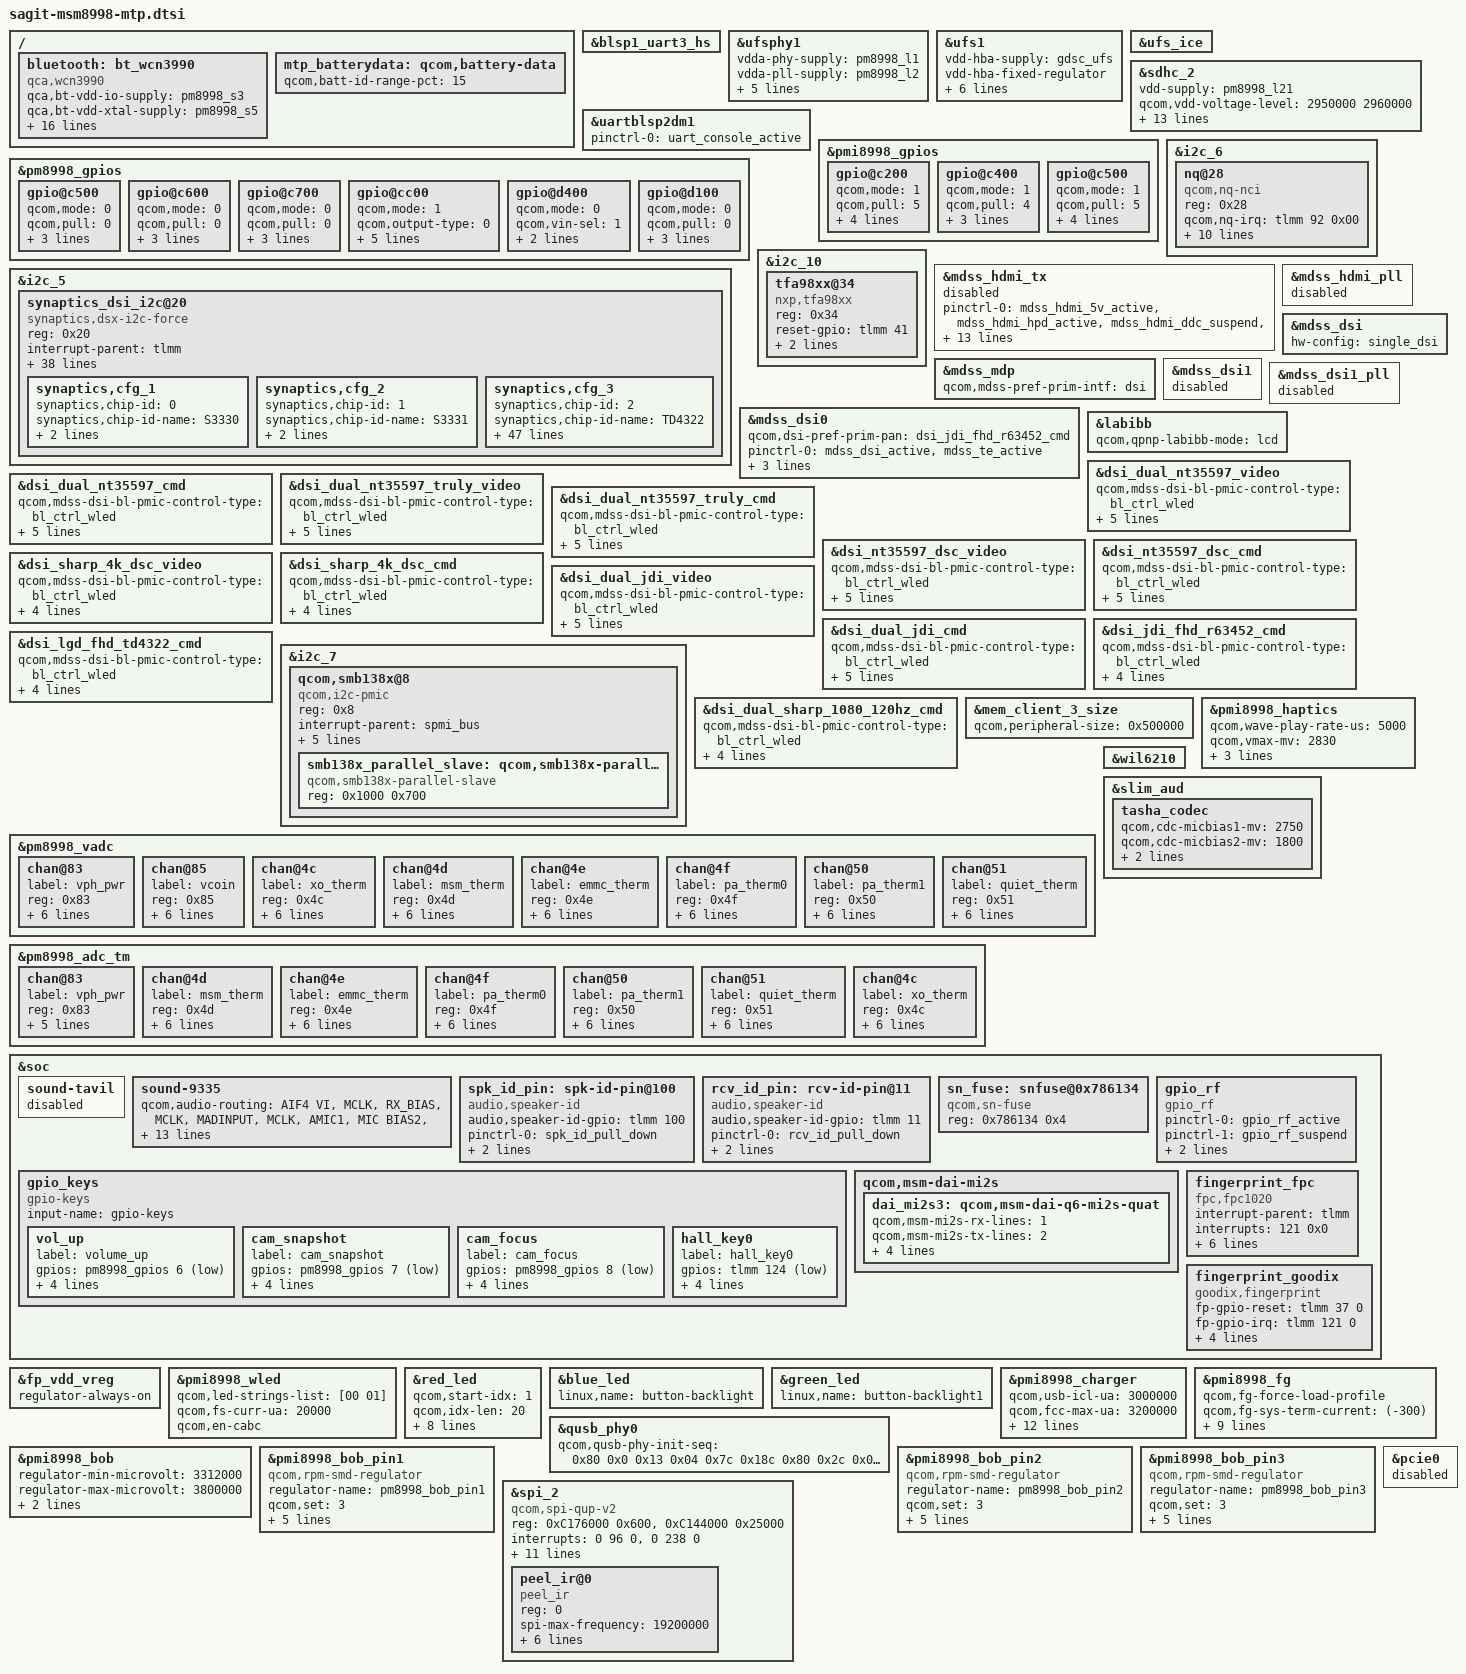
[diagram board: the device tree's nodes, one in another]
/* Copyright (c) 2016, The Linux Foundation. All rights reserved.
 * Copyright (C) 2018 XiaoMi, Inc.
 *
 * This program is free software; you can redistribute it and/or modify
 * it under the terms of the GNU General Public License version 2 and
 * only version 2 as published by the Free Software Foundation.
 *
 * This program is distributed in the hope that it will be useful,
 * but WITHOUT ANY WARRANTY; without even the implied warranty of
 * MERCHANTABILITY or FITNESS FOR A PARTICULAR PURPOSE.  See the
 * GNU General Public License for more details.
 */

#include <dt-bindings/interrupt-controller/irq.h>
#include "msm8998-pinctrl.dtsi"
#include "sagit-camera-sensor-mtp.dtsi"

/ {
	bluetooth: bt_wcn3990 {
		compatible = "qca,wcn3990";
		qca,bt-vdd-io-supply = <&pm8998_s3>;
		qca,bt-vdd-xtal-supply = <&pm8998_s5>;
		qca,bt-vdd-core-supply = <&pm8998_l7>;
		qca,bt-vdd-pa-supply = <&pm8998_l17>;
		qca,bt-vdd-ldo-supply = <&pm8998_l25>;
		qca,bt-chip-pwd-supply = <&pmi8998_bob_pin1>;
		clocks = <&clock_gcc clk_rf_clk2_pin>;
		clock-names = "rf_clk2";

		qca,bt-vdd-io-voltage-level = <1352000 1352000>;
		qca,bt-vdd-xtal-voltage-level = <2040000 2040000>;
		qca,bt-vdd-core-voltage-level = <1800000 1800000>;
		qca,bt-vdd-pa-voltage-level = <1304000 1304000>;
		qca,bt-vdd-ldo-voltage-level = <3312000 3312000>;
		qca,bt-chip-pwd-voltage-level = <3600000 3600000>;

		qca,bt-vdd-io-current-level = <1>; /* LPM/PFM */
		qca,bt-vdd-xtal-current-level = <1>; /* LPM/PFM */
		qca,bt-vdd-core-current-level = <1>; /* LPM/PFM */
		qca,bt-vdd-pa-current-level = <1>; /* LPM/PFM */
		qca,bt-vdd-ldo-current-level = <1>; /* LPM/PFM */
	};
};

&blsp1_uart3_hs {
	status = "ok";
};

&ufsphy1 {
	vdda-phy-supply = <&pm8998_l1>;
	vdda-pll-supply = <&pm8998_l2>;
	vddp-ref-clk-supply = <&pm8998_l26>;
	vdda-phy-max-microamp = <51400>;
	vdda-pll-max-microamp = <14600>;
	vddp-ref-clk-max-microamp = <100>;
	vddp-ref-clk-always-on;
	status = "ok";
};

&ufs1 {
	vdd-hba-supply = <&gdsc_ufs>;
	vdd-hba-fixed-regulator;
	vcc-supply = <&pm8998_l20>;
	vccq-supply = <&pm8998_l26>;
	vccq2-supply = <&pm8998_s4>;
	vcc-max-microamp = <750000>;
	vccq-max-microamp = <560000>;
	vccq2-max-microamp = <750000>;
	status = "ok";
};

&ufs_ice {
	status = "ok";
};

&sdhc_2 {
	vdd-supply = <&pm8998_l21>;
	qcom,vdd-voltage-level = <2950000 2960000>;
	qcom,vdd-current-level = <200 800000>;

	vdd-io-supply = <&pm8998_l13>;
	qcom,vdd-io-voltage-level = <1808000 2960000>;
	qcom,vdd-io-current-level = <200 22000>;

	pinctrl-names = "active", "sleep";
	pinctrl-0 = <&sdc2_clk_on  &sdc2_cmd_on &sdc2_data_on &sdc2_cd_on>;
	pinctrl-1 = <&sdc2_clk_off &sdc2_cmd_off &sdc2_data_off &sdc2_cd_off>;

	qcom,clk-rates = <400000 20000000 25000000
				50000000 100000000 200000000>;
	qcom,bus-speed-mode = "SDR12", "SDR25", "SDR50", "DDR50", "SDR104";

	cd-gpios = <&tlmm 95 0x1>;

	status = "ok";
};

&uartblsp2dm1 {
	status = "ok";
	pinctrl-names = "default";
	pinctrl-0 = <&uart_console_active>;
};

&pm8998_gpios {
	/* GPIO 6 for Vol+ Key */
	gpio@c500 {
		status = "okay";
		qcom,mode = <0>;
		qcom,pull = <0>;
		qcom,vin-sel = <0>;
		qcom,src-sel = <0>;
		qcom,out-strength = <1>;
	};

	/* GPIO 7 for Snapshot Key */
	gpio@c600 {
		status = "okay";
		qcom,mode = <0>;
		qcom,pull = <0>;
		qcom,vin-sel = <0>;
		qcom,src-sel = <0>;
		qcom,out-strength = <1>;
	};

	/* GPIO 8 for Focus Key */
	gpio@c700 {
		status = "okay";
		qcom,mode = <0>;
		qcom,pull = <0>;
		qcom,vin-sel = <0>;
		qcom,src-sel = <0>;
		qcom,out-strength = <1>;
	};

	gpio@cc00 { /* GPIO 13 */
		qcom,mode = <1>;
		qcom,output-type = <0>;
		qcom,pull = <5>;
		qcom,vin-sel = <0>;
		qcom,out-strength = <1>;
		qcom,src-sel = <3>;
		qcom,master-en = <1>;
		status = "okay";
	};

	/* GPIO 21 (NFC_CLK_REQ) */
	gpio@d400 {
		qcom,mode = <0>;
		qcom,vin-sel = <1>;
		qcom,src-sel = <0>;
		qcom,master-en = <1>;
		status = "okay";
	};

	/* GPIO 18 SMB138X */
	gpio@d100 {
		qcom,mode = <0>;
		qcom,pull = <0>;
		qcom,vin-sel = <0>;
		qcom,src-sel = <0>;
		qcom,master-en = <1>;
		status = "okay";
	};
};

&pmi8998_gpios {
	/* GPIO 3 for NS5S1153 AUDIO_SEL pin */
	gpio@c200 {
		status = "okay";
		qcom,mode = <1>;	/* Digital out */
		qcom,pull = <5>;	/* No pull */
		qcom,vin-sel = <1>;	/* 1.8v */
		qcom,src-sel = <0>;
		qcom,out-strength = <1>;
		qcom,master-en = <1>;
	};

	/* GPIO 5 for INFARED_DRV */
	gpio@c400 {
		status = "okay";
		qcom,mode = <1>;         /* QPNP_PIN_MODE_DIG_OUT */
		qcom,pull = <4>;                        /*PULL DOWN 10uA*/
		qcom,src-sel = <2>;             /*SPECIAL FUNCTION 1*/
		qcom,master-en = <1>;           /*ENABLE GPIO*/
		qcom,out-strength = <2>;        /*Medium strength current*/
	};

	/* GPIO 6 for the internal QNOVO discharge FET control signal */
	gpio@c500 {
		status = "okay";
		qcom,mode = <1>;
		qcom,pull = <5>;
		qcom,vin-sel = <0>;
		qcom,src-sel = <2>;
		qcom,out-strength = <1>;
		qcom,master-en = <1>;
	};
};

&i2c_5 {
	status = "okay";
	synaptics_dsi_i2c@20 {
		compatible = "synaptics,dsx-i2c-force";
		reg = <0x20>;
		interrupt-parent = <&tlmm>;
		interrupts = <125 0x2008>;
		vdd-supply = <&pm8998_l6>;
		lab-supply = <&lab_regulator>;
		ibb-supply = <&ibb_regulator>;
		disp-supply = <&pm8998_l14>;
		avdd-supply = <&disp_vddts_vreg>;
		synaptics,pwr-reg-name = "vdd";
		synaptics,lab-reg-name = "lab";
		synaptics,ibb-reg-name = "ibb";
		synaptics,disp-reg-name = "disp";
		synaptics,bus-reg-name = "avdd";
		synaptics,ub-i2c-addr = <0x2c>;
		pinctrl-names = "pmx_ts_active", "pmx_ts_suspend";
		pinctrl-0 = <&ts_active>;
		pinctrl-1 = <&ts_int_suspend &ts_reset_suspend>;
		synaptics,mdss-dsi-reset = <&tlmm 8 0>;
		synaptics,reset-gpio = <&tlmm 89 0x00>;
		synaptics,irq-gpio = <&tlmm 125 0x2008>;
		synaptics,reset-gpio-name = "dsx_reset";
		synaptics,irq-gpio-name = "dsx_irq";
		synaptics,irq-on-state = <0>;
		synaptics,irq-flags = <0x2008>; /* IRQF_ONESHOT | IRQF_TRIGGER_LOW */
		synaptics,power-delay-ms = <5>;
		synaptics,reset-delay-ms = <200>;
		synaptics,reset-active-ms = <5>;
		synaptics,power-on-state = <1>;
		synaptics,reset-on-state = <0>;
		synaptics,mdss-reset-state = <1>;
		synaptics,panel-is-incell;
		synaptics,cap-button-codes = <158 139 102>;
		synaptics,short-jdi-25 = "000: 0xfb\n001: 0xef\n002: 0xff\n003: 0xff\n004: 0x18\n005: 0x00\n006: 0x00";
		synaptics,short-jdi-26 = "000: 0x03\n001: 0x00\n002: 0x00\n003: 0x00\n004: 0x00\n005: 0x00\n006: 0x00";
		clock-names = "iface_clk", "core_clk";
		clocks = <&clock_gcc clk_gcc_blsp1_ahb_clk>,
			 <&clock_gcc clk_gcc_blsp1_qup5_i2c_apps_clk>;
		synaptics,guest-serialization-as-lockdown;
		synaptics,tp-id-byte = /bits/ 8 <0>;
		synaptics,config-array-size = <3>;
		synaptics,cfg_1 {
			synaptics,chip-id = <0>;
			synaptics,chip-id-name = "S3330";
			synaptics,tp-id = /bits/ 8 <0x31>;
			synaptics,fw-name = "synaptics_jdi_3330_c1.fw";
		};
		synaptics,cfg_2 {
			synaptics,chip-id = <1>;
			synaptics,chip-id-name = "S3331";
			synaptics,tp-id = /bits/ 8 <0x31>;
			synaptics,fw-name = "synaptics_jdi_3331_c1.fw";
		};
		synaptics,cfg_3 {
			synaptics,chip-id = <2>;
			synaptics,chip-id-name = "TD4322";
			synaptics,chip-is-tddi;

			synaptics,factory-param;
			synaptics,tddi-short-limit_b = <150>;
			synaptics,tddi-noise-limit	= <60>;
			synaptics,tddi-extend-ee-short-reset-dur = <60>;
			synaptics,tddi-extend-ee-short-int_dur = <150>;
			synaptics,tddi-extend-ee-short-tx-on-count = <146>;
			synaptics,tddi-extend-ee-short-rx-on-count = <146>;
			synaptics,tddi-extend-ee-short-test-limit-part1 = <180>;
			synaptics,tddi-extend-ee-short-test-limit-part2 = <0>;

			synaptics,tddi-open-test-int-dur-one = <145>;
			synaptics,tddi-open-test-int-dur-two = <15>;
			synaptics,tddi-open-test-limit-phase2-lower = <50>;

			synaptics,tddi-b7-open-test-int-dur-one = <23>;
			synaptics,tddi-b7-open-test-int-dur-two = <27>;
			synaptics,tddi-b7-open-test-limit-phase2-lower = <0>;
			synaptics,tddi-b7-open-test-limit-phase2-upper = <115>;
			synaptics,button-count = <2>;
			synaptics,abs-0d-open-factor = <9>;
			synaptics,abs-0d-open-test-limit = <30>;

			synaptics,elec-open-test-tx-on-count = <2>;
			synaptics,elec-open-test-rx-on-count = <2>;
			synaptics,elec-open-int-dur-one = <10>;
			synaptics,elec-open-int-dur-two = <15>;
			synaptics,elec-open-test-limit-one = <0>;
			synaptics,elec-open-test-limit-two = <50>;

			synaptics,disp-pre-on-sleep = <10>;
			synaptics,disp-post-on-sleep = <10>;
			synaptics,disp-pre-off-sleep = <10>;
			synaptics,disp-post-off-sleep = <0>;
			synaptics,lab-pre-on-sleep = <0>;
			synaptics,lab-post-on-sleep = <10>;
			synaptics,lab-pre-off-sleep = <10>;
			synaptics,lab-post-off-sleep = <0>;
			synaptics,ibb-pre-on-sleep = <0>;
			synaptics,ibb-post-on-sleep = <10>;
			synaptics,ibb-pre-off-sleep = <10>;
			synaptics,ibb-post-off-sleep = <0>;
			synaptics,tp-id = /bits/ 8 <0x34>;
			synaptics,fw-name = "synaptics_lgd_4322_c1.fw";
		};
	};
};

&i2c_6 { /* BLSP1 QUP6 (NFC) */
	status = "okay";
	nq@28 {
		compatible = "qcom,nq-nci";
		reg = <0x28>;
		qcom,nq-irq = <&tlmm 92 0x00>;
		qcom,nq-ven = <&tlmm 12 0x00>;
		qcom,nq-firm = <&tlmm 93 0x00>;
		qcom,nq-clkreq = <&pm8998_gpios 21 0x00>;
		qcom,nq-esepwr = <&tlmm 116 0x00>;
		interrupt-parent = <&tlmm>;
		qcom,clk-src = "BBCLK3";
		interrupts = <92 0>;
		interrupt-names = "nfc_irq";
		pinctrl-names = "nfc_active", "nfc_suspend";
		pinctrl-0 = <&nfc_int_active &nfc_enable_active>;
		pinctrl-1 = <&nfc_int_suspend &nfc_enable_suspend>;
		clocks = <&clock_gcc clk_ln_bb_clk3_pin>;
		clock-names = "ref_clk";
	};
};

&i2c_10 { /* BLSP2 QUP4 (Audio Smart Pa)*/
	status = "okay";
	tfa98xx@34 {
		compatible = "nxp,tfa98xx";
		reg = <0x34>;
		reset-gpio = <&tlmm 41 0>;
		irq-gpio = <&tlmm 42 0>;
		spk-id = <&spk_id_pin>;
	};
};

&mdss_hdmi_tx {
	status = "disabled";
	pinctrl-names = "hdmi_hpd_active", "hdmi_ddc_active", "hdmi_cec_active",
				"hdmi_active", "hdmi_sleep";
	pinctrl-0 = <&mdss_hdmi_5v_active  &mdss_hdmi_hpd_active
			&mdss_hdmi_ddc_suspend &mdss_hdmi_cec_suspend>;
	pinctrl-1 = <&mdss_hdmi_5v_active &mdss_hdmi_hpd_active
			&mdss_hdmi_ddc_active &mdss_hdmi_cec_suspend>;
	pinctrl-2 = <&mdss_hdmi_5v_active &mdss_hdmi_hpd_active
			&mdss_hdmi_cec_active &mdss_hdmi_ddc_suspend>;
	pinctrl-3 = <&mdss_hdmi_5v_active &mdss_hdmi_hpd_active
			&mdss_hdmi_ddc_active &mdss_hdmi_cec_active>;
	pinctrl-4 = <&mdss_hdmi_5v_suspend &mdss_hdmi_hpd_suspend
			&mdss_hdmi_ddc_suspend &mdss_hdmi_cec_suspend>;
};

&mdss_hdmi_pll {
	status = "disabled";
};

&mdss_mdp {
	qcom,mdss-pref-prim-intf = "dsi";
};

&mdss_dsi {
	hw-config = "single_dsi";
};

&mdss_dsi0 {
	qcom,dsi-pref-prim-pan = <&dsi_jdi_fhd_r63452_cmd>;
	pinctrl-names = "mdss_default", "mdss_sleep";
	pinctrl-0 = <&mdss_dsi_active &mdss_te_active>;
	pinctrl-1 = <&mdss_dsi_suspend &mdss_te_suspend>;
	qcom,platform-reset-gpio = <&tlmm 94 0>;
	qcom,platform-te-gpio = <&tlmm 10 0>;
};

&mdss_dsi1 {
	status = "disabled";
};

&mdss_dsi1_pll {
	status = "disabled";
};

&labibb {
	status = "ok";
	qcom,qpnp-labibb-mode = "lcd";
};

&dsi_dual_nt35597_video {
	qcom,mdss-dsi-bl-pmic-control-type = "bl_ctrl_wled";
	qcom,mdss-dsi-bl-min-level = <1>;
	qcom,mdss-dsi-bl-max-level = <4095>;
	qcom,mdss-dsi-mode-sel-gpio-state = "dual_port";
	qcom,panel-supply-entries = <&dsi_panel_pwr_supply>;
};

&dsi_dual_nt35597_cmd {
	qcom,mdss-dsi-bl-pmic-control-type = "bl_ctrl_wled";
	qcom,mdss-dsi-bl-min-level = <1>;
	qcom,mdss-dsi-bl-max-level = <4095>;
	qcom,mdss-dsi-mode-sel-gpio-state = "dual_port";
	qcom,panel-supply-entries = <&dsi_panel_pwr_supply>;
};

&dsi_dual_nt35597_truly_video {
	qcom,mdss-dsi-bl-pmic-control-type = "bl_ctrl_wled";
	qcom,mdss-dsi-bl-min-level = <1>;
	qcom,mdss-dsi-bl-max-level = <4095>;
	qcom,mdss-dsi-mode-sel-gpio-state = "dual_port";
	qcom,panel-supply-entries = <&dsi_panel_pwr_supply>;
};

&dsi_dual_nt35597_truly_cmd {
	qcom,mdss-dsi-bl-pmic-control-type = "bl_ctrl_wled";
	qcom,mdss-dsi-bl-min-level = <1>;
	qcom,mdss-dsi-bl-max-level = <4095>;
	qcom,mdss-dsi-mode-sel-gpio-state = "dual_port";
	qcom,panel-supply-entries = <&dsi_panel_pwr_supply>;
};

&dsi_nt35597_dsc_video {
	qcom,mdss-dsi-bl-pmic-control-type = "bl_ctrl_wled";
	qcom,mdss-dsi-bl-min-level = <1>;
	qcom,mdss-dsi-bl-max-level = <4095>;
	qcom,mdss-dsi-mode-sel-gpio-state = "single_port";
	qcom,panel-supply-entries = <&dsi_panel_pwr_supply>;
};

&dsi_nt35597_dsc_cmd {
	qcom,mdss-dsi-bl-pmic-control-type = "bl_ctrl_wled";
	qcom,mdss-dsi-bl-min-level = <1>;
	qcom,mdss-dsi-bl-max-level = <4095>;
	qcom,mdss-dsi-mode-sel-gpio-state = "single_port";
	qcom,panel-supply-entries = <&dsi_panel_pwr_supply>;
};

&dsi_sharp_4k_dsc_video {
	qcom,mdss-dsi-bl-pmic-control-type = "bl_ctrl_wled";
	qcom,mdss-dsi-bl-min-level = <1>;
	qcom,mdss-dsi-bl-max-level = <4095>;
	qcom,panel-supply-entries = <&dsi_panel_pwr_supply>;
};

&dsi_sharp_4k_dsc_cmd {
	qcom,mdss-dsi-bl-pmic-control-type = "bl_ctrl_wled";
	qcom,mdss-dsi-bl-min-level = <1>;
	qcom,mdss-dsi-bl-max-level = <4095>;
	qcom,panel-supply-entries = <&dsi_panel_pwr_supply>;
};

&dsi_dual_jdi_video {
	qcom,mdss-dsi-bl-pmic-control-type = "bl_ctrl_wled";
	qcom,mdss-dsi-bl-min-level = <1>;
	qcom,mdss-dsi-bl-max-level = <4095>;
	qcom,5v-boost-gpio = <&tlmm 51 0>;
	qcom,panel-supply-entries = <&dsi_panel_pwr_supply>;
};

&dsi_dual_jdi_cmd {
	qcom,mdss-dsi-bl-pmic-control-type = "bl_ctrl_wled";
	qcom,mdss-dsi-bl-min-level = <1>;
	qcom,mdss-dsi-bl-max-level = <4095>;
	qcom,5v-boost-gpio = <&tlmm 51 0>;
	qcom,panel-supply-entries = <&dsi_panel_pwr_supply>;
};

&dsi_jdi_fhd_r63452_cmd {
	qcom,mdss-dsi-bl-pmic-control-type = "bl_ctrl_wled";
	qcom,mdss-dsi-bl-min-level = <1>;
	qcom,mdss-dsi-bl-max-level = <4095>;
	qcom,panel-supply-entries = <&dsi_panel_pwr_supply>;
};

&dsi_lgd_fhd_td4322_cmd {
	qcom,mdss-dsi-bl-pmic-control-type = "bl_ctrl_wled";
	qcom,mdss-dsi-bl-min-level = <1>;
	qcom,mdss-dsi-bl-max-level = <4095>;
	qcom,panel-supply-entries = <&dsi_panel_pwr_supply_lgd_td4322>;
};

&i2c_7 {
	status = "okay";
	qcom,smb138x@8 {
		compatible = "qcom,i2c-pmic";
		reg = <0x8>;
		#address-cells = <2>;
		#size-cells = <0>;
		interrupt-parent = <&spmi_bus>;
		interrupts = <0x0 0xd1 0x0 IRQ_TYPE_LEVEL_LOW>;
		interrupt_names = "smb138x";
		interrupt-controller;
		#interrupt-cells = <3>;
		qcom,periph-map = <0x10 0x11 0x12 0x13 0x14 0x16 0x36>;
		smb138x_parallel_slave: qcom,smb138x-parallel-slave@1000 {
			compatible = "qcom,smb138x-parallel-slave";
			reg = <0x1000 0x700>;
		};
	};
};

&dsi_dual_sharp_1080_120hz_cmd {
	qcom,mdss-dsi-bl-pmic-control-type = "bl_ctrl_wled";
	qcom,mdss-dsi-bl-min-level = <1>;
	qcom,mdss-dsi-bl-max-level = <4095>;
	qcom,panel-supply-entries = <&dsi_panel_pwr_supply>;
};

&mem_client_3_size {
	qcom,peripheral-size = <0x500000>;
};

&pmi8998_haptics {
	status = "okay";
	qcom,wave-play-rate-us = <5000>;
	qcom,vmax-mv = <2830>;
	qcom,wave-shape = "sine";
	qcom,brake-pattern = [03 02 00 00];
	qcom,misc-trim-error-rc19p2-clk-reg-present;
};

&pm8998_vadc {
	chan@83 {
		label = "vph_pwr";
		reg = <0x83>;
		qcom,decimation = <2>;
		qcom,pre-div-channel-scaling = <1>;
		qcom,calibration-type = "absolute";
		qcom,scale-function = <0>;
		qcom,hw-settle-time = <0>;
		qcom,fast-avg-setup = <0>;
	};

	chan@85 {
		label = "vcoin";
		reg = <0x85>;
		qcom,decimation = <2>;
		qcom,pre-div-channel-scaling = <1>;
		qcom,calibration-type = "absolute";
		qcom,scale-function = <0>;
		qcom,hw-settle-time = <0>;
		qcom,fast-avg-setup = <0>;
	};

	chan@4c {
		label = "xo_therm";
		reg = <0x4c>;
		qcom,decimation = <2>;
		qcom,pre-div-channel-scaling = <0>;
		qcom,calibration-type = "ratiometric";
		qcom,scale-function = <4>;
		qcom,hw-settle-time = <2>;
		qcom,fast-avg-setup = <0>;
	};

	chan@4d {
		label = "msm_therm";
		reg = <0x4d>;
		qcom,decimation = <2>;
		qcom,pre-div-channel-scaling = <0>;
		qcom,calibration-type = "ratiometric";
		qcom,scale-function = <2>;
		qcom,hw-settle-time = <2>;
		qcom,fast-avg-setup = <0>;
	};

	chan@4e {
		label = "emmc_therm";
		reg = <0x4e>;
		qcom,decimation = <2>;
		qcom,pre-div-channel-scaling = <0>;
		qcom,calibration-type = "ratiometric";
		qcom,scale-function = <2>;
		qcom,hw-settle-time = <2>;
		qcom,fast-avg-setup = <0>;
	};

	chan@4f {
		label = "pa_therm0";
		reg = <0x4f>;
		qcom,decimation = <2>;
		qcom,pre-div-channel-scaling = <0>;
		qcom,calibration-type = "ratiometric";
		qcom,scale-function = <2>;
		qcom,hw-settle-time = <2>;
		qcom,fast-avg-setup = <0>;
	};

	chan@50 {
		label = "pa_therm1";
		reg = <0x50>;
		qcom,decimation = <2>;
		qcom,pre-div-channel-scaling = <0>;
		qcom,calibration-type = "ratiometric";
		qcom,scale-function = <2>;
		qcom,hw-settle-time = <2>;
		qcom,fast-avg-setup = <0>;
	};

	chan@51 {
		label = "quiet_therm";
		reg = <0x51>;
		qcom,decimation = <2>;
		qcom,pre-div-channel-scaling = <0>;
		qcom,calibration-type = "ratiometric";
		qcom,scale-function = <2>;
		qcom,hw-settle-time = <2>;
		qcom,fast-avg-setup = <0>;
	};
};

&pm8998_adc_tm {
	chan@83 {
		label = "vph_pwr";
		reg = <0x83>;
		qcom,pre-div-channel-scaling = <1>;
		qcom,calibration-type = "absolute";
		qcom,scale-function = <0>;
		qcom,hw-settle-time = <0>;
		qcom,btm-channel-number = <0x60>;
	};

	chan@4d {
		label = "msm_therm";
		reg = <0x4d>;
		qcom,pre-div-channel-scaling = <0>;
		qcom,calibration-type = "ratiometric";
		qcom,scale-function = <2>;
		qcom,hw-settle-time = <2>;
		qcom,btm-channel-number = <0x68>;
		qcom,thermal-node;
	};

	chan@4e {
		label = "emmc_therm";
		reg = <0x4e>;
		qcom,pre-div-channel-scaling = <0>;
		qcom,calibration-type = "ratiometric";
		qcom,scale-function = <2>;
		qcom,hw-settle-time = <2>;
		qcom,btm-channel-number = <0x80>;
		qcom,thermal-node;
	};

	chan@4f {
		label = "pa_therm0";
		reg = <0x4f>;
		qcom,pre-div-channel-scaling = <0>;
		qcom,calibration-type = "ratiometric";
		qcom,scale-function = <2>;
		qcom,hw-settle-time = <2>;
		qcom,btm-channel-number = <0x88>;
		qcom,thermal-node;
	};

	chan@50 {
		label = "pa_therm1";
		reg = <0x50>;
		qcom,pre-div-channel-scaling = <0>;
		qcom,calibration-type = "ratiometric";
		qcom,scale-function = <2>;
		qcom,hw-settle-time = <2>;
		qcom,btm-channel-number = <0x90>;
		qcom,thermal-node;
	};

	chan@51 {
		label = "quiet_therm";
		reg = <0x51>;
		qcom,pre-div-channel-scaling = <0>;
		qcom,calibration-type = "ratiometric";
		qcom,scale-function = <2>;
		qcom,hw-settle-time = <2>;
		qcom,btm-channel-number = <0x70>;
		qcom,thermal-node;
	};

	chan@4c {
		label = "xo_therm";
		reg = <0x4c>;
		qcom,pre-div-channel-scaling = <0>;
		qcom,calibration-type = "ratiometric";
		qcom,scale-function = <4>;
		qcom,hw-settle-time = <2>;
		qcom,btm-channel-number = <0x78>;
		qcom,thermal-node;
	};
};

&wil6210 {
	status = "ok";
};

&slim_aud {
	tasha_codec {
		qcom,cdc-micbias1-mv = <2750>;
		qcom,cdc-micbias2-mv = <1800>;
		qcom,cdc-micbias3-mv = <1800>;
		qcom,cdc-micbias4-mv = <2750>;
	};
};

&soc {
	sound-tavil {
		status = "disabled";
	};

	sound-9335 {
		qcom,audio-routing =
			"AIF4 VI", "MCLK",
			"RX_BIAS", "MCLK",
			"MADINPUT", "MCLK",
			"AMIC1", "MIC BIAS2",
			"MIC BIAS2", "Handset Mic",
			"AMIC2", "MIC BIAS2",
			"MIC BIAS2", "Headset Mic",
			"AMIC3", "MIC BIAS1",
			"MIC BIAS1", "ANCRight Headset Mic",
			"AMIC4", "MIC BIAS1",
			"MIC BIAS1", "ANCLeft Headset Mic",
			"AMIC5", "MIC BIAS4",
			"MIC BIAS4", "Handset Mic",
			"AMIC6", "MIC BIAS4",
			"MIC BIAS4", "Analog Mic6";

		qcom,wsa-max-devs = <0>;
		qcom,msm-mbhc-hphl-swh = <1>;
		qcom,us-euro-gpios = <&wcd_us_euro_gpio>;

		qcom,asel-gpio = <&pmi8998_gpios 3 0x00>;
		qcom,hsdet-gpio = <&tlmm 8 0x01>;

		qcom,spk-id-pin = <&spk_id_pin>;
		qcom,rcv-id-pin = <&rcv_id_pin>;
	};

	spk_id_pin: spk-id-pin@100 {
		compatible = "audio,speaker-id";
		audio,speaker-id-gpio = <&tlmm 100 0x00>;
		pinctrl-names = "pull_down", "pull_up", "no_pull";
		pinctrl-0 = <&spk_id_pull_down>;
		pinctrl-1 = <&spk_id_pull_up>;
		pinctrl-2 = <&spk_id_no_pull>;
	};

	rcv_id_pin: rcv-id-pin@11 {
		compatible = "audio,speaker-id";
		audio,speaker-id-gpio = <&tlmm 11 0x00>;
		pinctrl-names = "pull_down", "pull_up", "no_pull";
		pinctrl-0 = <&rcv_id_pull_down>;
		pinctrl-1 = <&rcv_id_pull_up>;
		pinctrl-2 = <&rcv_id_no_pull>;
	};

	sn_fuse: snfuse@0x786134 {
		compatible = "qcom,sn-fuse";
		reg = <0x786134 0x4>;
		reg-names = "sn-base";
	};

	gpio_keys {
		compatible = "gpio-keys";
		input-name = "gpio-keys";
		status = "okay";

		vol_up {
			label = "volume_up";
			gpios = <&pm8998_gpios 6 0x1>;
			linux,input-type = <1>;
			linux,code = <115>;
			gpio-key,wakeup;
			debounce-interval = <15>;
		};

		cam_snapshot {
			label = "cam_snapshot";
			gpios = <&pm8998_gpios 7 0x1>;
			linux,input-type = <1>;
			linux,code = <766>;
			gpio-key,wakeup;
			debounce-interval = <15>;
		};

		cam_focus {
			label = "cam_focus";
			gpios = <&pm8998_gpios 8 0x1>;
			linux,input-type = <1>;
			linux,code = <528>;
			gpio-key,wakeup;
			debounce-interval = <15>;
		};

		hall_key0 {
			label = "hall_key0";
			gpios = <&tlmm 124 0x01>;
			linux,input-type = <5>;
			linux,code = <0>;
			gpio-key,wakeup;
			debounce-interval = <15>;
		};
	};

	gpio_rf {
		pinctrl-names = "tlmm_gpio_rf_active","tlmm_gpio_rf_suspend";
		pinctrl-0 = <&gpio_rf_active>;
		pinctrl-1 = <&gpio_rf_suspend>;
		compatible = "gpio_rf";
		gpios = <&tlmm 119 0x01>;
		debounce-interval = <15>;
	};

	qcom,msm-dai-mi2s {
		dai_mi2s3: qcom,msm-dai-q6-mi2s-quat {
			qcom,msm-mi2s-rx-lines = <1>;
			qcom,msm-mi2s-tx-lines = <2>;
			pinctrl-names = "default", "sleep";
			pinctrl-0 = <&quat_mi2s_active
				     &quat_mi2s_sd0_active
				     &quat_mi2s_sd1_active>;
			pinctrl-1 = <&quat_mi2s_sleep
				     &quat_mi2s_sd0_sleep
				     &quat_mi2s_sd1_sleep>;
		};
	};

	fingerprint_fpc {
		status = "ok";
		compatible = "fpc,fpc1020";
		interrupt-parent = <&tlmm>;
		interrupts = <121 0x0>;
		fpc,gpio_rst    = <&tlmm 37 0x0>;
		fpc,gpio_irq    = <&tlmm 121 0x0>;
		vdd_ana-supply  = <&fp_vdd_vreg>;
		/* fpc,enable-on-boot; */
		/* fpc,enable-wakeup; */

		pinctrl-names = "fpc1020_reset_reset",
			"fpc1020_reset_active",
			"fpc1020_irq_active";

		pinctrl-0 = <&msm_gpio_37>;
		pinctrl-1 = <&msm_gpio_37_output_high>;
		pinctrl-2 = <&msm_gpio_121>;
	};

	fingerprint_goodix {
		compatible = "goodix,fingerprint";
		fp-gpio-reset = <&tlmm 37 0>;
		fp-gpio-irq = <&tlmm 121 0>;
		pinctrl-names = "pmx_fp_active", "pmx_fp_suspend";
		pinctrl-0 = <&fp_active>;
		pinctrl-1 = <&fp_suspend>;
		clock-names = "iface_clk", "core_clk";
		clocks = <&clock_gcc clk_gcc_blsp2_ahb_clk>,
			<&clock_gcc clk_gcc_blsp2_qup6_spi_apps_clk>;
		status = "ok";
	};
};

&fp_vdd_vreg {
	regulator-always-on;
};

&pmi8998_wled {
	qcom,led-strings-list = [00 01];
	qcom,fs-curr-ua = <20000>;
	qcom,en-cabc;
};

/* Red led was used for powersupply of White led */
&red_led {
	qcom,start-idx = <1>;
	qcom,idx-len = <20>;
	qcom,duty-pcts = [00 06 10 20 32 44 54 5e 64 64
			64 5e 54 44 32 20 10 06 00 00];
	qcom,lut-flags = <3>;
	qcom,pause-lo = <0>;
	qcom,pause-hi = <0>;
	qcom,ramp-step-ms = <128>;
	qcom,use-blink;
	linux,name = "white";
};

/* Blue led was used for powersupply of left button key backlight */
&blue_led {
		 linux,name = "button-backlight";
};

/* Green led was used for powersupply of right button key backlight */
&green_led {
		 linux,name = "button-backlight1";
};
&pmi8998_charger {
		 qcom,usb-icl-ua = <3000000>;
		 qcom,fcc-max-ua = <3200000>;
		 qcom,fcc-low-temp-delta = <2875000>;
		 qcom,fcc-hot-temp-delta = <1600000>;
		 qcom,fcc-cool-temp-delta = <2225000>;
		 qcom,auto-recharge-soc;

		 qcom,thermal-mitigation
								= <1800000 1600000 1400000 1200000 1000000 1000000 1000000>;
		 qcom,thermal-mitigation-dcp
								= <1800000 1600000 1400000 1200000 1000000 1000000 1000000>;
		 qcom,thermal-mitigation-qc3
								= <3000000 2425000 2125000 1825000 1525000 1225000 750000>;
		 qcom,thermal-mitigation-qc2
								= <1600000 1400000 1200000 1000000 900000 900000 550000>;
};
&pmi8998_fg {
		 qcom,fg-force-load-profile;
		 qcom,fg-sys-term-current = <(-300)>;
		 qcom,fg-chg-term-current = <200>;
		 qcom,fg-auto-recharge-soc;
		 qcom,fg-recharge-soc-thr = <99>;
		 qcom,fg-cutoff-voltage = <3400>;
		 qcom,fg-empty-voltage = <3100>;
		 qcom,fg-jeita-hyst-temp = <0>;
		 qcom,fg-jeita-thresholds = <0 15 45 58>;
		 qcom,fg-esr-clamp-mohms = <60>;
		 qcom,fg-batt-temp-delta = <6>;
};
/{
	mtp_batterydata: qcom,battery-data {
		qcom,batt-id-range-pct = <15>;
		#include "batterydata-c1-atl-3350mAh.dtsi"
		#include "batterydata-c1-sdi-3440mAh.dtsi"
		#include "batterydata-itech-3020mAh.dtsi"
	};
};

&qusb_phy0 {
	qcom,qusb-phy-init-seq =
				/* <value reg_offset> */
				<0x80 0x0
				0x13 0x04
				0x7c 0x18c
				0x80 0x2c
				0x0a 0x184
				0xf0 0x23c
				0x0d 0x240>;
};

&pmi8998_bob {
		 regulator-min-microvolt = <3312000>;
		 regulator-max-microvolt = <3800000>;
		 qcom,bob-pwm-threshold-current = <2000000>;
		 qcom,init-bob-mode = <2>;
		 status = "okay";
};
&pmi8998_bob_pin1 {
		 compatible = "qcom,rpm-smd-regulator";
		 regulator-name = "pm8998_bob_pin1";
		 qcom,set = <3>;
		 regulator-min-microvolt = <3312000>;
		 regulator-max-microvolt = <3800000>;
		 qcom,bob-pwm-threshold-current = <2000000>;
		 qcom,init-bob-mode = <2>;
		 qcom,use-pin-ctrl-voltage1;
};
&pmi8998_bob_pin2 {
		 compatible = "qcom,rpm-smd-regulator";
		 regulator-name = "pm8998_bob_pin2";
		 qcom,set = <3>;
		 regulator-min-microvolt = <3312000>;
		 regulator-max-microvolt = <3800000>;
		 qcom,bob-pwm-threshold-current = <2000000>;
		 qcom,init-bob-mode = <2>;
		 qcom,use-pin-ctrl-voltage2;
};
&pmi8998_bob_pin3 {
		 compatible = "qcom,rpm-smd-regulator";
		 regulator-name = "pm8998_bob_pin3";
		 qcom,set = <3>;
		 regulator-min-microvolt = <3312000>;
		 regulator-max-microvolt = <3800000>;
		 qcom,bob-pwm-threshold-current = <2000000>;
		 qcom,init-bob-mode = <2>;
		 qcom,use-pin-ctrl-voltage3;
};

&spi_2 {
		 compatible = "qcom,spi-qup-v2";
		 #address-cells = <1>;
		 #size-cells = <0>;
		 reg-names = "spi_physical", "spi_bam_physical";
		 reg = <0xC176000 0x600>,
		 <0xC144000 0x25000>;
		 interrupt-names = "spi_irq", "spi_bam_irq";
		 interrupts = <0 96 0>, <0 238 0>;
		 spi-max-frequency = <19200000>;
		 qcom,use-bam;
		 qcom,ver-reg-exists;
		 qcom,bam-consumer-pipe-index = <8>;
		 qcom,bam-producer-pipe-index = <9>;
		 qcom,master-id = <86>;
		 qcom,use-pinctrl;
		 pinctrl-names = "spi_default", "spi_sleep";
		 pinctrl-0 = <&spi_2_active>;
		 pinctrl-1 = <&spi_2_sleep>;
		 clock-names = "iface_clk", "core_clk";
		 clocks = <&clock_gcc clk_gcc_blsp1_ahb_clk>,
				<&clock_gcc clk_gcc_blsp1_qup2_spi_apps_clk>;
		 status = "ok";
		 peel_ir@0 {
				compatible = "peel_ir";
				reg = <0>;
				spi-max-frequency = <19200000>;
				peel_ir,lr-gpio = <73>;
				peel_ir,lr-gpio-valid = <1>;
				peel_ir,spi-bpw = <32>;
				peel_ir,spi-clk-speed= <960000>;
				peel_ir,spi-mode = <0>;
				peel_ir,peel-field = <2345>;
				status = "ok";
		 };
};

&pcie0 {
		 status = "disabled";
};
